# CY8C5888LTI_LP097 register map
File version: 0.1
CY8C58LP
Registers are 8-bit, read-write, no defined reset value unless marked. A register's access mark holds for its fields unless they carry their own. Offsets are from the block's base; lines under a group give offsets from that group; [hi:lo] are bit positions; {n}, {i} and the like mark numbered series; 'fields as' and 'values as' point back to an identical list; <NAME> marks a mode.

## Memory map
0x00000000 Timer_1ms
0x00000000 Timer_2secs
0x00000000 UART_LOG — UART

## Timer_1ms
Base 0x00000000
0x40006406 Timer_1ms_COUNTER 16-bit — UDB.A0 - Current Down Counter Value
0x40006426 Timer_1ms_PERIOD 16-bit — UDB.D0 - Assigned Period
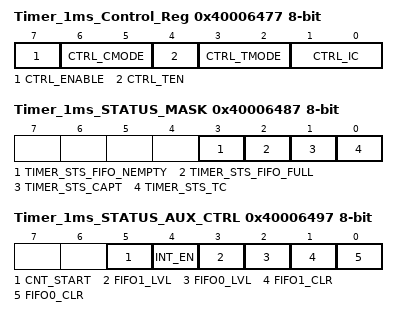
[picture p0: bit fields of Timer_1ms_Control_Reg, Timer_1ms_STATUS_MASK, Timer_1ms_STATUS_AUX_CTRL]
0x40006477 Timer_1ms_Control_Reg — UDB Control Register - Assigned Control Register Value
  [7] CTRL_ENABLE — Enable the Timer
  [6:5] CTRL_CMODE — Capture Mode
  [4] CTRL_TEN — Trigger Enable Bit
  [3:2] CTRL_TMODE — Trigger Mode
  [1:0] CTRL_IC — Interrupt Count
0x40006487 Timer_1ms_STATUS_MASK — UDB Status bits Interrupt Mask Enable Register
  [3] TIMER_STS_FIFO_NEMPTY ro — FIFO Empty status
  [2] TIMER_STS_FIFO_FULL ro — FIFO Full Status
  [1] TIMER_STS_CAPT ro — Enables the Interrupt on Capture
  [0] TIMER_STS_TC ro — Enables the Interrupt on TC
0x40006497 Timer_1ms_STATUS_AUX_CTRL — UDB Auxilliary Control Register
  [5] CNT_START — FIFO0 clear
    0=E_CNT_START0 (Disable counter); 1=E_CNT_START1 (Enable counter)
  [4] INT_EN
    0=E_INT_EN0 (Interrupt disabled); 1=E_INT_EN1 (Interrupt enabled)
  [3] FIFO1_LVL — FIFO level
    0=E_FIFO_LVL_0 (FIFO LVL: input mode: FIFO not full; output mode: FIFO not empty); 1=E_FIFO_LVL_1 (FIFO LVL: input mode: FIFO at least 1/2 empty; output mode: FIFO at least 1/2 full)
  [2] FIFO0_LVL — FIFO level
    values as FIFO1_LVL
  [1] FIFO1_CLR — FIFO1 clear
    0=E_FIFO_CLR_0 (Normal FIFO operation); 1=E_FIFO_CLR_1 (Clear FIFO state)
  [0] FIFO0_CLR — FIFO0 clear
    values as FIFO1_CLR

## Timer_2secs
Base 0x00000000
0x40006504 Timer_2secs_COUNTER 24-bit — UDB.A0 - Current Down Counter Value
0x40006524 Timer_2secs_PERIOD 24-bit — UDB.D0 - Assigned Period
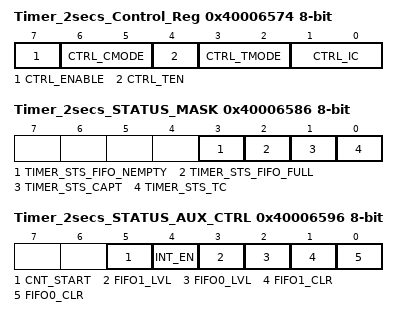
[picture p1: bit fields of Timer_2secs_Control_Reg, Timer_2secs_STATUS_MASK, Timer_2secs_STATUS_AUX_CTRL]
0x40006574 Timer_2secs_Control_Reg — UDB Control Register - Assigned Control Register Value
  [7] CTRL_ENABLE — Enable the Timer
  [6:5] CTRL_CMODE — Capture Mode
  [4] CTRL_TEN — Trigger Enable Bit
  [3:2] CTRL_TMODE — Trigger Mode
  [1:0] CTRL_IC — Interrupt Count
0x40006586 Timer_2secs_STATUS_MASK — UDB Status bits Interrupt Mask Enable Register
  fields as Timer_1ms.Timer_1ms_STATUS_MASK
0x40006596 Timer_2secs_STATUS_AUX_CTRL — UDB Auxilliary Control Register
  fields as Timer_1ms.Timer_1ms_STATUS_AUX_CTRL

## UART_LOG — UART
Base 0x00000000
0x4000652A RX_UART_LOG_RX_ADDRESS1 — RX Address1 Register
0x4000653A RX_UART_LOG_RX_ADDRESS2 — RX Address2 Register
0x40006548 TX_UART_LOG_TX_DATA — TX Data Register
0x4000654A RX_UART_LOG_RX_DATA — RX Data Register
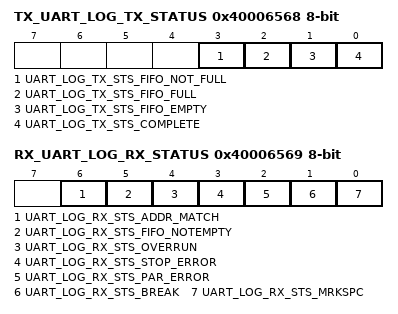
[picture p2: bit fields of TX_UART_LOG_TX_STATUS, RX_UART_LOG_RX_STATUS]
0x40006568 TX_UART_LOG_TX_STATUS — TX status register
  [3] UART_LOG_TX_STS_FIFO_NOT_FULL ro, [2] UART_LOG_TX_STS_FIFO_FULL ro, [1] UART_LOG_TX_STS_FIFO_EMPTY ro, [0] UART_LOG_TX_STS_COMPLETE ro
0x40006569 RX_UART_LOG_RX_STATUS — RX status register
  [6] UART_LOG_RX_STS_ADDR_MATCH ro, [5] UART_LOG_RX_STS_FIFO_NOTEMPTY ro, [4] UART_LOG_RX_STS_OVERRUN ro, [3] UART_LOG_RX_STS_STOP_ERROR ro, [2] UART_LOG_RX_STS_PAR_ERROR ro, [1] UART_LOG_RX_STS_BREAK ro, [0] UART_LOG_RX_STS_MRKSPC ro
